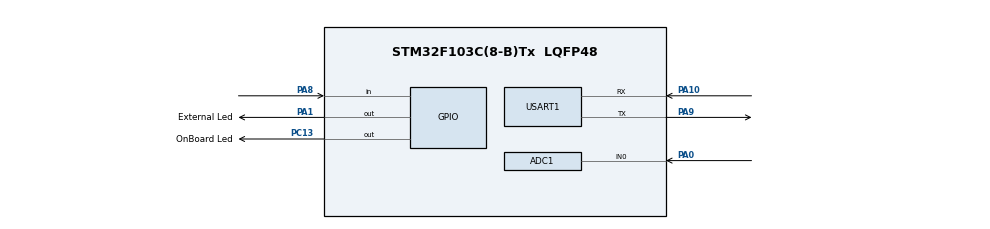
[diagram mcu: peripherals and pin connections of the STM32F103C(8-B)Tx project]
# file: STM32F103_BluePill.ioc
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ADC1.Channel-0\#ChannelRegularConversion=ADC_CHANNEL_0
ADC1.NbrOfConversionFlag=1
ADC1.Rank-0\#ChannelRegularConversion=1
ADC1.SamplingTime-0\#ChannelRegularConversion=ADC_SAMPLETIME_1CYCLE_5
ADC1.master=1
FREERTOS.Tasks01=defaultTask,0,128,StartDefaultTask,Default,NULL,Dynamic,NULL,NULL;myTask02,-2,128,StartTask02,Default,NULL,Dynamic,NULL,NULL
Mcu.Family=STM32F1
Mcu.Name=STM32F103C(8-B)Tx
Mcu.Package=LQFP48
NVIC.PriorityGroup=NVIC_PRIORITYGROUP_4
NVIC.TIM1_UP_IRQn=true\:0\:0\:false\:false\:true\:false\:false\:true
NVIC.TimeBase=TIM1_UP_IRQn
NVIC.TimeBaseIP=TIM1
PA0-WKUP.Signal=ADCx_IN0
PA1.GPIO_Label=External Led
PA1.Signal=GPIO_Output
PA10.Mode=Asynchronous
PA10.Signal=USART1_RX
PA8.Signal=GPIO_Input
PA9.Mode=Asynchronous
PA9.Signal=USART1_TX
PC13-TAMPER-RTC.GPIO_Label=OnBoard Led
PC13-TAMPER-RTC.Signal=GPIO_Output
ProjectManager.HeapSize=0x200
ProjectManager.StackSize=0x400
ProjectManager.TargetToolchain=MDK-ARM V5
RCC.APB1Freq_Value=8000000
RCC.APB2Freq_Value=8000000
SH.ADCx_IN0.0=ADC1_IN0,IN0
USART1.VirtualMode=VM_ASYNC
VP_FREERTOS_VS_CMSIS_V1.Mode=CMSIS_V1
VP_SYS_VS_ND.Mode=No_Debug
VP_SYS_VS_tim1.Mode=TIM1
board=custom

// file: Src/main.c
/* USER CODE BEGIN Header */
/**
  ******************************************************************************
  * @file           : main.c
  * @brief          : Main program body
  ******************************************************************************
  * @attention
  *
  * <h2><center>&copy; Copyright (c) 2020 STMicroelectronics.
  * All rights reserved.</center></h2>
  *
  * This software component is licensed by ST under Ultimate Liberty license
  * SLA0044, the "License"; You may not use this file except in compliance with
  * the License. You may obtain a copy of the License at:
  *                             www.st.com/SLA0044
  *
  ******************************************************************************
  */
/* USER CODE END Header */

#include "main.h"
#include "cmsis_os.h"

ADC_HandleTypeDef hadc1;

UART_HandleTypeDef huart1;

osThreadId defaultTaskHandle;
osThreadId myTask02Handle;

void SystemClock_Config(void);
static void MX_GPIO_Init(void);
static void MX_ADC1_Init(void);
static void MX_USART1_UART_Init(void);
void StartDefaultTask(void const * argument);
void StartTask02(void const * argument);

/* USER CODE BEGIN 0 */
uint32_t adc_value=0;
/* USER CODE END 0 */

int main(void)
{

  /* MCU Configuration--------------------------------------------------------*/

  /* Reset of all peripherals, Initializes the Flash interface and the Systick. */
  HAL_Init();

  /* Configure the system clock */
  SystemClock_Config();

  /* Initialize all configured peripherals */
  MX_GPIO_Init();
  MX_ADC1_Init();
  MX_USART1_UART_Init();

  /* Create the thread(s) */
  /* definition and creation of defaultTask */
  osThreadDef(defaultTask, StartDefaultTask, osPriorityNormal, 0, 128);
  defaultTaskHandle = osThreadCreate(osThread(defaultTask), NULL);

  /* definition and creation of myTask02 */
  osThreadDef(myTask02, StartTask02, osPriorityLow, 0, 128);
  myTask02Handle = osThreadCreate(osThread(myTask02), NULL);

  /* Start scheduler */
  osKernelStart();

  /* We should never get here as control is now taken by the scheduler */

  /* Infinite loop */
  while (1)
  {

  }
}

void SystemClock_Config(void)
{
  RCC_OscInitTypeDef RCC_OscInitStruct = {0};
  RCC_ClkInitTypeDef RCC_ClkInitStruct = {0};
  RCC_PeriphCLKInitTypeDef PeriphClkInit = {0};

  /** Initializes the CPU, AHB and APB busses clocks
  */
  RCC_OscInitStruct.OscillatorType = RCC_OSCILLATORTYPE_HSI;
  RCC_OscInitStruct.HSIState = RCC_HSI_ON;
  RCC_OscInitStruct.HSICalibrationValue = RCC_HSICALIBRATION_DEFAULT;
  RCC_OscInitStruct.PLL.PLLState = RCC_PLL_NONE;
  if (HAL_RCC_OscConfig(&RCC_OscInitStruct) != HAL_OK)
  {
    Error_Handler();
  }
  /** Initializes the CPU, AHB and APB busses clocks
  */
  RCC_ClkInitStruct.ClockType = RCC_CLOCKTYPE_HCLK|RCC_CLOCKTYPE_SYSCLK
                              |RCC_CLOCKTYPE_PCLK1|RCC_CLOCKTYPE_PCLK2;
  RCC_ClkInitStruct.SYSCLKSource = RCC_SYSCLKSOURCE_HSI;
  RCC_ClkInitStruct.AHBCLKDivider = RCC_SYSCLK_DIV1;
  RCC_ClkInitStruct.APB1CLKDivider = RCC_HCLK_DIV1;
  RCC_ClkInitStruct.APB2CLKDivider = RCC_HCLK_DIV1;

  if (HAL_RCC_ClockConfig(&RCC_ClkInitStruct, FLASH_LATENCY_0) != HAL_OK)
  {
    Error_Handler();
  }
  PeriphClkInit.PeriphClockSelection = RCC_PERIPHCLK_ADC;
  PeriphClkInit.AdcClockSelection = RCC_ADCPCLK2_DIV2;
  if (HAL_RCCEx_PeriphCLKConfig(&PeriphClkInit) != HAL_OK)
  {
    Error_Handler();
  }
}

static void MX_ADC1_Init(void)
{

  ADC_ChannelConfTypeDef sConfig = {0};

  /** Common config
  */
  hadc1.Instance = ADC1;
  hadc1.Init.ScanConvMode = ADC_SCAN_DISABLE;
  hadc1.Init.ContinuousConvMode = DISABLE;
  hadc1.Init.DiscontinuousConvMode = DISABLE;
  hadc1.Init.ExternalTrigConv = ADC_SOFTWARE_START;
  hadc1.Init.DataAlign = ADC_DATAALIGN_RIGHT;
  hadc1.Init.NbrOfConversion = 1;
  if (HAL_ADC_Init(&hadc1) != HAL_OK)
  {
    Error_Handler();
  }
  /** Configure Regular Channel
  */
  sConfig.Channel = ADC_CHANNEL_0;
  sConfig.Rank = ADC_REGULAR_RANK_1;
  sConfig.SamplingTime = ADC_SAMPLETIME_1CYCLE_5;
  if (HAL_ADC_ConfigChannel(&hadc1, &sConfig) != HAL_OK)
  {
    Error_Handler();
  }

}

static void MX_USART1_UART_Init(void)
{

  huart1.Instance = USART1;
  huart1.Init.BaudRate = 115200;
  huart1.Init.WordLength = UART_WORDLENGTH_8B;
  huart1.Init.StopBits = UART_STOPBITS_1;
  huart1.Init.Parity = UART_PARITY_NONE;
  huart1.Init.Mode = UART_MODE_TX_RX;
  huart1.Init.HwFlowCtl = UART_HWCONTROL_NONE;
  huart1.Init.OverSampling = UART_OVERSAMPLING_16;
  if (HAL_UART_Init(&huart1) != HAL_OK)
  {
    Error_Handler();
  }

}

static void MX_GPIO_Init(void)
{
  GPIO_InitTypeDef GPIO_InitStruct = {0};

  /* GPIO Ports Clock Enable */
  __HAL_RCC_GPIOC_CLK_ENABLE();
  __HAL_RCC_GPIOA_CLK_ENABLE();

  /*Configure GPIO pin Output Level */
  HAL_GPIO_WritePin(OnBoard_Led_GPIO_Port, OnBoard_Led_Pin, GPIO_PIN_RESET);

  /*Configure GPIO pin Output Level */
  HAL_GPIO_WritePin(External_Led_GPIO_Port, External_Led_Pin, GPIO_PIN_RESET);

  /*Configure GPIO pin : OnBoard_Led_Pin */
  GPIO_InitStruct.Pin = OnBoard_Led_Pin;
  GPIO_InitStruct.Mode = GPIO_MODE_OUTPUT_PP;
  GPIO_InitStruct.Pull = GPIO_NOPULL;
  GPIO_InitStruct.Speed = GPIO_SPEED_FREQ_LOW;
  HAL_GPIO_Init(OnBoard_Led_GPIO_Port, &GPIO_InitStruct);

  /*Configure GPIO pin : External_Led_Pin */
  GPIO_InitStruct.Pin = External_Led_Pin;
  GPIO_InitStruct.Mode = GPIO_MODE_OUTPUT_PP;
  GPIO_InitStruct.Pull = GPIO_NOPULL;
  GPIO_InitStruct.Speed = GPIO_SPEED_FREQ_LOW;
  HAL_GPIO_Init(External_Led_GPIO_Port, &GPIO_InitStruct);

  /*Configure GPIO pin : PA8 */
  GPIO_InitStruct.Pin = GPIO_PIN_8;
  GPIO_InitStruct.Mode = GPIO_MODE_INPUT;
  GPIO_InitStruct.Pull = GPIO_NOPULL;
  HAL_GPIO_Init(GPIOA, &GPIO_InitStruct);

}

void StartDefaultTask(void const * argument)
{

  /* USER CODE BEGIN 5 */
  /* Infinite loop */
  for(;;)
  {
    HAL_GPIO_TogglePin ( OnBoard_Led_GPIO_Port, OnBoard_Led_Pin);
		HAL_ADC_Start(&hadc1);
		if(HAL_ADC_PollForConversion(&hadc1, 5) == HAL_OK)
		{
			adc_value = HAL_ADC_GetValue(&hadc1);
		}
		HAL_ADC_Stop(&hadc1);
		vTaskDelay (500 / portTICK_PERIOD_MS);
  }
  /* USER CODE END 5 */
}

void StartTask02(void const * argument)
{
  /* USER CODE BEGIN StartTask02 */
  /* Infinite loop */
  for(;;)
  {
    HAL_GPIO_TogglePin ( External_Led_GPIO_Port, External_Led_Pin);
		vTaskDelay (700 / portTICK_PERIOD_MS);
  }
  /* USER CODE END StartTask02 */
}

void HAL_TIM_PeriodElapsedCallback(TIM_HandleTypeDef *htim)
{
  if (htim->Instance == TIM1) {
    HAL_IncTick();
  }
}

void Error_Handler(void)
{
}

/************************ (C) COPYRIGHT STMicroelectronics *****END OF FILE****/
